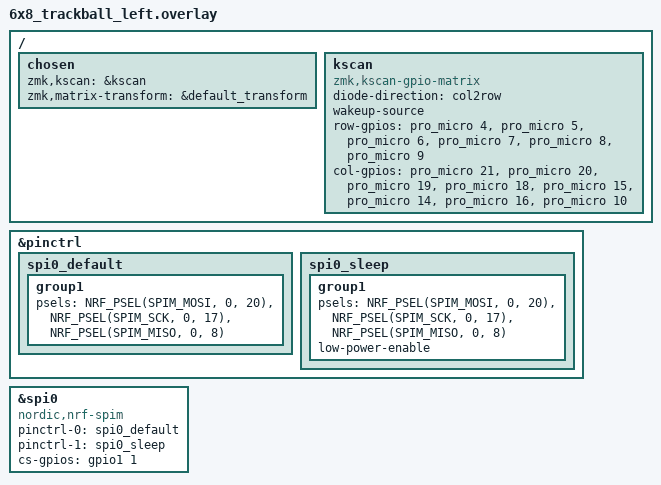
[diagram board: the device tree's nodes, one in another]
#include "6x8_trackball.dtsi"
/ {
    chosen {
        zmk,kscan = &kscan;
        zmk,matrix-transform = &default_transform;
    };

    kscan: kscan {
        compatible = "zmk,kscan-gpio-matrix";
        diode-direction = "col2row";
        wakeup-source;

        row-gpios
            = <&pro_micro 4 (GPIO_ACTIVE_HIGH | GPIO_PULL_DOWN)>
            , <&pro_micro 5 (GPIO_ACTIVE_HIGH | GPIO_PULL_DOWN)>
            , <&pro_micro 6 (GPIO_ACTIVE_HIGH | GPIO_PULL_DOWN)>
            , <&pro_micro 7 (GPIO_ACTIVE_HIGH | GPIO_PULL_DOWN)>
            , <&pro_micro 8 (GPIO_ACTIVE_HIGH | GPIO_PULL_DOWN)>
            , <&pro_micro 9 (GPIO_ACTIVE_HIGH | GPIO_PULL_DOWN)>
            ;

        col-gpios
            = <&pro_micro 21 GPIO_ACTIVE_HIGH>
            , <&pro_micro 20 GPIO_ACTIVE_HIGH>
            , <&pro_micro 19 GPIO_ACTIVE_HIGH>
            , <&pro_micro 18 GPIO_ACTIVE_HIGH>
            , <&pro_micro 15 GPIO_ACTIVE_HIGH>
            , <&pro_micro 14 GPIO_ACTIVE_HIGH>
            , <&pro_micro 16 GPIO_ACTIVE_HIGH>
            , <&pro_micro 10 GPIO_ACTIVE_HIGH>
            ;
    };
};

&pinctrl {
    spi0_default: spi0_default {
        group1 {
            psels = <NRF_PSEL(SPIM_MOSI, 0, 20)>,    // Set P0.20 (D3) as MOSI
                    <NRF_PSEL(SPIM_SCK, 0, 17)>,     // Set P0.17 (D2) as SCK
                    <NRF_PSEL(SPIM_MISO, 0, 8)>;     // Set P0.08 (D0) as MISO
        };
    };
    
    spi0_sleep: spi0_sleep {
        group1 {
            psels = <NRF_PSEL(SPIM_MOSI, 0, 20)>,    // Set P0.20 (D3) as MOSI
                    <NRF_PSEL(SPIM_SCK, 0, 17)>,     // Set P0.17 (D2) as SCK
                    <NRF_PSEL(SPIM_MISO, 0, 8)>;     // Set P0.08 (D0) as MISO
            low-power-enable;
        };
    };
};

nice_view_spi: &spi0 {
    compatible = "nordic,nrf-spim";
    pinctrl-0 = <&spi0_default>;
    pinctrl-1 = <&spi0_sleep>;
    pinctrl-names = "default", "sleep";
    cs-gpios = <&gpio1 1 GPIO_ACTIVE_HIGH>;
};
